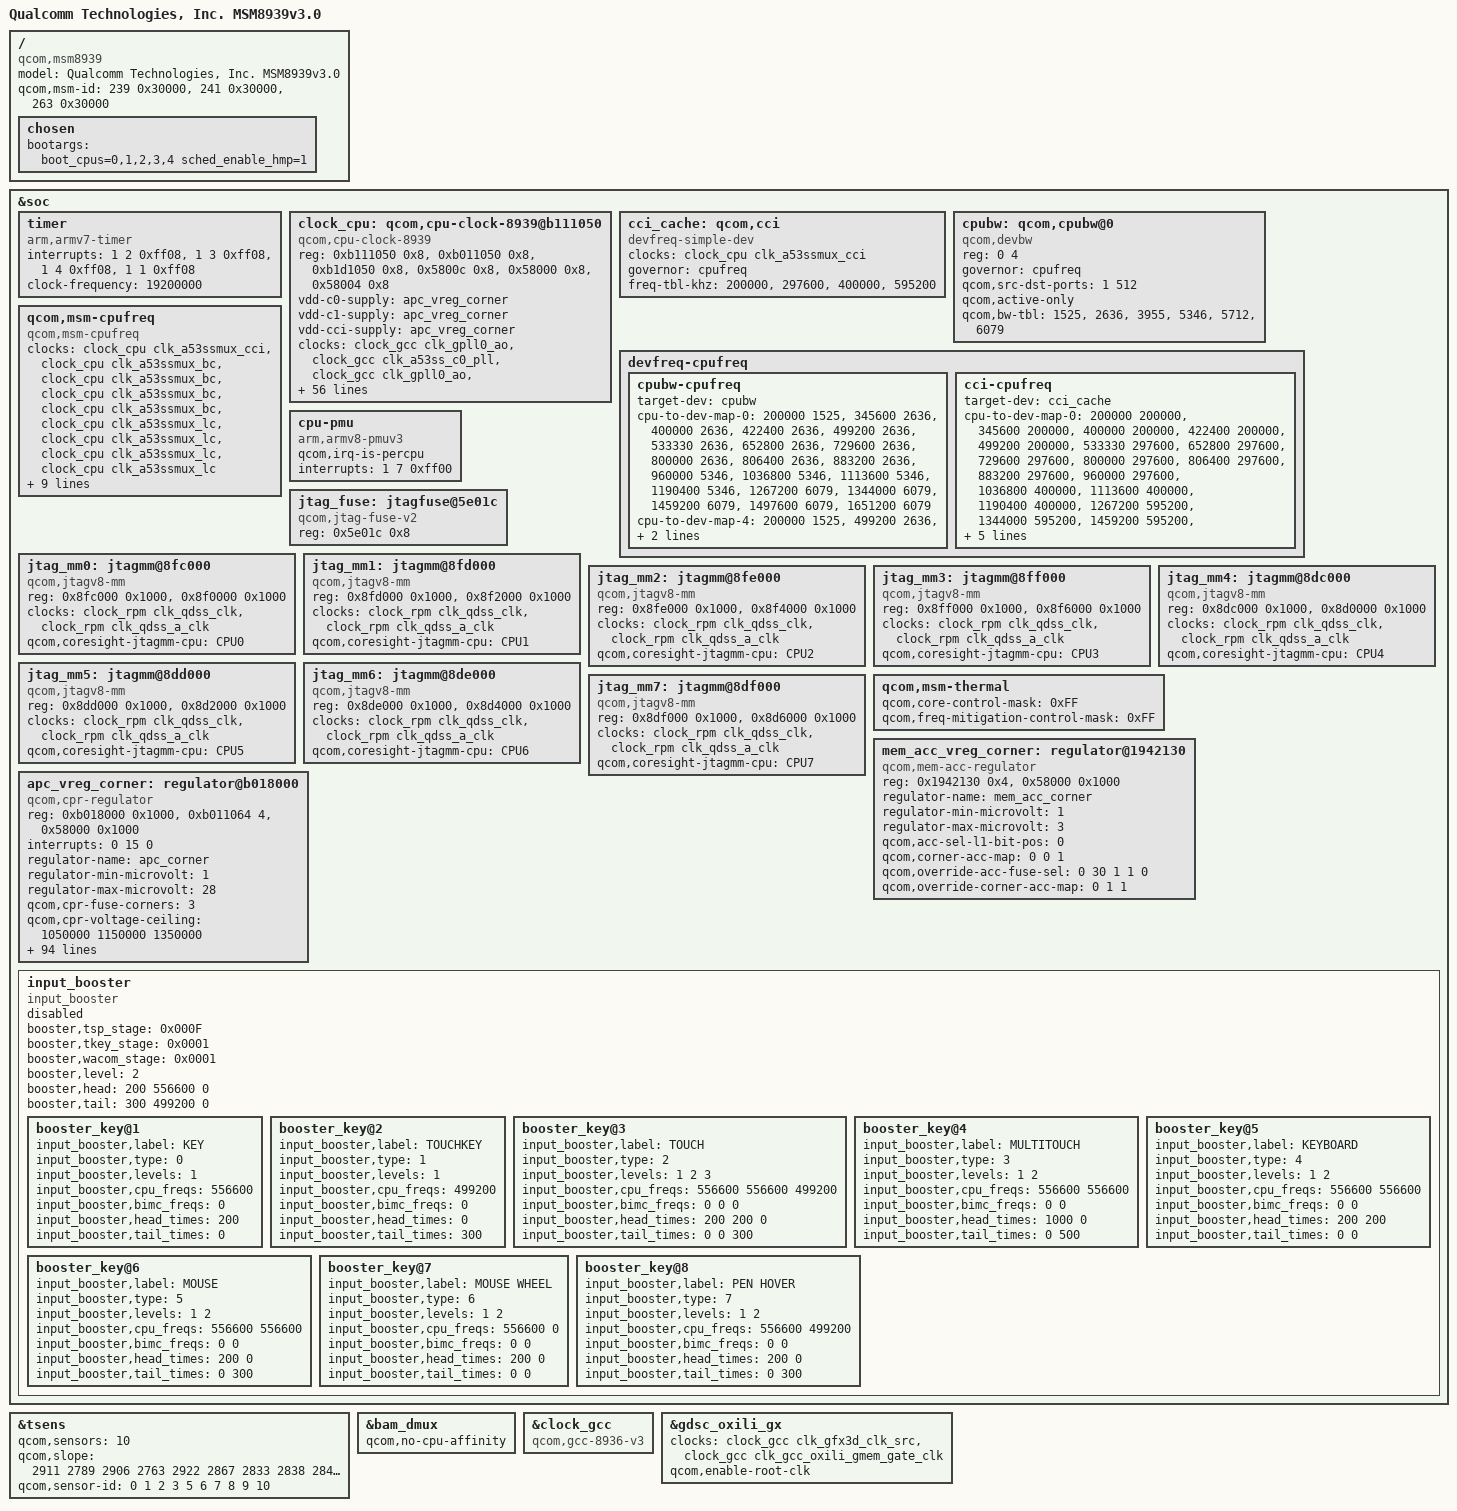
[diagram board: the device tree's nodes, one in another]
/*
 * Copyright (c) 2015, The Linux Foundation. All rights reserved.
 *
 * This program is free software; you can redistribute it and/or modify
 * it under the terms of the GNU General Public License version 2 and
 * only version 2 as published by the Free Software Foundation.
 *
 * This program is distributed in the hope that it will be useful,
 * but WITHOUT ANY WARRANTY; without even the implied warranty of
 * MERCHANTABILITY or FITNESS FOR A PARTICULAR PURPOSE.  See the
 * GNU General Public License for more details.
 */

#include "skeleton64.dtsi"
#include <dt-bindings/clock/msm-clocks-8936.h>
#include <dt-bindings/clock/msm-cpu-clocks-8939.h>
#include "msm8939-common.dtsi"
#include "msm8939-coresight.dtsi"
#include "msm8939-cpu.dtsi"
#include "msm8939-v3.0-pm.dtsi"
#include "msm8939-smem.dtsi"
#include "msm8939-smp2p.dtsi"
#include "msm8939-v3.0-gpu.dtsi"

/ {
	model = "Qualcomm Technologies, Inc. MSM8939v3.0";
	compatible = "qcom,msm8939";
	qcom,msm-id = <239 0x30000>, <241 0x30000>, <263 0x30000>;

	chosen {
		bootargs = "boot_cpus=0,1,2,3,4 sched_enable_hmp=1";
	};
};

&soc {
	timer {
		compatible = "arm,armv7-timer";
		interrupts = <1 2 0xff08>,
			     <1 3 0xff08>,
			     <1 4 0xff08>,
			     <1 1 0xff08>;
		clock-frequency = <19200000>;
	};

	clock_cpu: qcom,cpu-clock-8939@b111050 {
		compatible = "qcom,cpu-clock-8939";
		reg =   <0xb111050 0x8>,
			<0xb011050 0x8>,
			<0xb1d1050 0x8>,
			<0x5800c   0x8>,
			<0x58000   0x8>,
			<0x58004   0x8>;
		reg-names = "apcs-c0-rcg-base", "apcs-c1-rcg-base",
				"apcs-cci-rcg-base", "efuse", "efuse1",
				"efuse2";
		vdd-c0-supply = <&apc_vreg_corner>;
		vdd-c1-supply = <&apc_vreg_corner>;
		vdd-cci-supply = <&apc_vreg_corner>;
		clocks = <&clock_gcc clk_gpll0_ao>,
			 <&clock_gcc clk_a53ss_c0_pll>,
			 <&clock_gcc clk_gpll0_ao>,
			 <&clock_gcc clk_a53ss_c1_pll>,
			 <&clock_gcc clk_gpll0_ao>,
			 <&clock_gcc clk_a53ss_cci_pll>;
		clock-names = "clk-c0-4", "clk-c0-5",
				"clk-c1-4", "clk-c1-5",
				"clk-cci-4", "clk-cci-5";
		qcom,speed0-bin-v0-c0 =
			<          0 0>,
			<  400000000 3>,
			<  500000000 9>,
			<  800000000 12>,
			<  998400000 17>,
			< 1113600000 24>,
			< 1209600000 26>;

		qcom,speed0-bin-v0-c1 =
			<          0 0>,
			<  400000000 3>,
			<  800000000 9>,
			<  960000000 12>,
			< 1113600000 14>,
			< 1344000000 17>;

		qcom,speed0-bin-v0-cci =
			<          0 0>,
			<  200000000 3>,
			<  300000000 12>,
			<  400000000 15>,
			<  600000000 17>;

		qcom,speed2-bin-v0-c0 =
			<          0 0>,
			<  400000000 3>,
			<  500000000 9>,
			<  800000000 12>,
			<  998400000 17>,
			< 1113600000 24>,
			< 1209600000 26>;

		qcom,speed2-bin-v0-c1 =
			<          0 0>,
			<  400000000 3>,
			<  800000000 9>,
			<  806400000 10>,
			<  883200000 11>,
			<  960000000 12>,
			< 1036800000 13>,
			< 1113600000 14>,
			< 1190400000 15>,
			< 1267200000 16>,
			< 1344000000 17>,
			< 1420800000 18>,
			< 1459200000 20>,
			< 1497600000 21>;

		qcom,speed2-bin-v0-cci =
			<          0 0>,
			<  200000000 3>,
			<  300000000 12>,
			<  400000000 15>,
			<  600000000 17>;

		qcom,speed2-bin-v2-c0 =
			<          0 0>,
			<  400000000 3>,
			<  500000000 9>,
			<  800000000 12>,
			<  998400000 17>,
			< 1113600000 24>,
			< 1209600000 26>;

		qcom,speed2-bin-v2-c1 =
			<          0 0>,
			<  400000000 3>,
			<  800000000 9>,
			<  960000000 12>,
			< 1113600000 14>,
			< 1344000000 17>,
			< 1459200000 20>;

		qcom,speed2-bin-v2-cci =
			<          0 0>,
			<  200000000 3>,
			<  300000000 12>,
			<  400000000 15>,
			<  600000000 17>;

		qcom,speed4-bin-v0-c0 =
			<          0 0>,
			<  400000000 3>,
			<  500000000 9>,
			<  800000000 12>,
			<  998400000 17>,
			< 1113600000 24>,
			< 1209600000 26>;

		qcom,speed4-bin-v0-c1 =
			<          0 0>,
			<  400000000 3>,
			<  800000000 9>,
			<  960000000 12>,
			< 1113600000 14>,
			< 1344000000 17>,
			< 1459200000 20>,
			< 1497600000 21>,
			< 1651200000 26>;

		qcom,speed4-bin-v0-cci =
			<          0 0>,
			<  200000000 3>,
			<  300000000 12>,
			<  400000000 15>,
			<  600000000 17>;

		qcom,speed5-bin-v0-c0 =
			<          0 0>,
			<  400000000 3>,
			<  500000000 9>,
			<  800000000 12>,
			<  998400000 17>,
			< 1113600000 24>,
			< 1209600000 26>;

		qcom,speed5-bin-v0-c1 =
			<          0 0>,
			<  400000000 3>,
			<  800000000 9>,
			<  960000000 12>,
			< 1113600000 14>,
			< 1344000000 17>,
			< 1459200000 20>,
			< 1497600000 21>,
			< 1651200000 26>;

		qcom,speed5-bin-v0-cci =
			<          0 0>,
			<  200000000 3>,
			<  300000000 12>,
			<  400000000 15>,
			<  600000000 17>;

		qcom,speed5-bin-v6-c0 =
			<          0 0>,
			<  400000000 3>,
			<  500000000 9>,
			<  800000000 12>,
			<  998400000 17>,
			< 1113600000 24>,
			< 1209600000 26>;

		qcom,speed5-bin-v6-c1 =
			<          0 0>,
			<  400000000 3>,
			<  800000000 9>,
			<  960000000 12>,
			< 1113600000 14>,
			< 1344000000 17>,
			< 1459200000 20>,
			< 1497600000 21>,
			< 1651200000 26>;

		qcom,speed5-bin-v6-cci =
			<          0 0>,
			<  200000000 3>,
			<  300000000 12>,
			<  400000000 15>,
			<  600000000 17>;

		#clock-cells = <1>;
	};

	cci_cache: qcom,cci {
		compatible = "devfreq-simple-dev";
		clock-names = "devfreq_clk";
		clocks = <&clock_cpu clk_a53ssmux_cci>;
		governor = "cpufreq";
		freq-tbl-khz =
			<  200000 >,
			<  297600 >,
			<  400000 >,
			<  595200 >;
	};

	cpubw: qcom,cpubw@0 {
		reg = <0 4>;
		compatible = "qcom,devbw";
		governor = "cpufreq";
		qcom,src-dst-ports = <1 512>;
		qcom,active-only;
		qcom,bw-tbl =
			<  1525 /*  100   MHz */ >,
			<  2636 /*  172.8 MHz */ >,
			<  3955 /*  259.2 MHz */ >,
			<  5346 /*  350.4 MHz */ >,
			<  5712 /*  374.4 MHz */ >,
			<  6079 /*  398.4 MHz */ >;
	};

	devfreq-cpufreq {
		cpubw-cpufreq {
		target-dev = <&cpubw>;
		cpu-to-dev-map-0 =
			<  200000  1525 >,
			<  345600  2636 >,
			<  400000  2636 >,
			<  422400  2636 >,
			<  499200  2636 >,
			<  533330  2636 >,
			<  652800  2636 >,
			<  729600  2636 >,
			<  800000  2636 >,
			<  806400  2636 >,
			<  883200  2636 >,
			<  960000  5346 >,
			<  1036800 5346 >,
			<  1113600 5346 >,
			<  1190400 5346 >,
			<  1267200 6079 >,
			<  1344000 6079 >,
			<  1459200 6079 >,
			<  1497600 6079 >,
			<  1651200 6079 >;
		cpu-to-dev-map-4 =
			<  200000 1525 >,
			<  499200 2636 >,
			<  533330 2636 >,
			<  800000 5346 >,
			<  998400 6079 >,
			< 1113600 6079 >,
			< 1209600 6079 >;
		};

		cci-cpufreq {
		target-dev = <&cci_cache>;
		cpu-to-dev-map-0 =
			<  200000  200000 >,
			<  345600  200000 >,
			<  400000  200000 >,
			<  422400  200000 >,
			<  499200  200000 >,
			<  533330  297600 >,
			<  652800  297600 >,
			<  729600  297600 >,
			<  800000  297600 >,
			<  806400  297600 >,
			<  883200  297600 >,
			<  960000  297600 >,
			< 1036800  400000 >,
			< 1113600  400000 >,
			< 1190400  400000 >,
			< 1267200  595200 >,
			< 1344000  595200 >,
			< 1459200  595200 >,
			< 1497600  595200 >,
			< 1651200  595200 >;
		cpu-to-dev-map-4 =
			<  200000 200000 >,
			<  499200 297600 >,
			<  533330 297600 >,
			<  800000 297600 >,
			<  998400 595200 >,
			< 1113600 595200 >,
			< 1209600 595200 >;
		};
	};

	qcom,msm-cpufreq {
		compatible = "qcom,msm-cpufreq";
		clock-names = "l2_clk", "cpu0_clk", "cpu1_clk", "cpu2_clk",
				"cpu3_clk", "cpu4_clk", "cpu5_clk",
				"cpu6_clk", "cpu7_clk";
		clocks = <&clock_cpu clk_a53ssmux_cci>,
			 <&clock_cpu clk_a53ssmux_bc>,
			 <&clock_cpu clk_a53ssmux_bc>,
			 <&clock_cpu clk_a53ssmux_bc>,
			 <&clock_cpu clk_a53ssmux_bc>,
			 <&clock_cpu clk_a53ssmux_lc>,
			 <&clock_cpu clk_a53ssmux_lc>,
			 <&clock_cpu clk_a53ssmux_lc>,
			 <&clock_cpu clk_a53ssmux_lc>;

		qcom,governor-per-policy;

		qcom,cpufreq-table-0 =
			 <  200000 >,
			 <  345600 >,
			 <  400000 >,
			 <  422400 >,
			 <  499200 >,
			 <  533330 >,
			 <  652800 >,
			 <  729600 >,
			 <  800000 >,
			 <  806400 >,
			 <  883200 >,
			 <  960000 >,
			 < 1036800 >,
			 < 1113600 >,
			 < 1190400 >,
			 < 1267200 >,
			 < 1344000 >,
			 < 1459200 >,
			 < 1497600 >,
			 < 1651200 >;

		qcom,cpufreq-table-4 =
			 <  200000 >,
			 <  249600 >,
			 <  400000 >,
			 <  499200 >,
			 <  533330 >,
			 <  800000 >,
			 <  998400 >,
			 < 1113600 >,
			 < 1209600 >;
	};

	cpu-pmu {
		compatible = "arm,armv8-pmuv3";
		qcom,irq-is-percpu;
		interrupts = <1 7 0xff00>;
	};

	jtag_fuse: jtagfuse@5e01c {
		compatible = "qcom,jtag-fuse-v2";
		reg = <0x5e01c 0x8>;
		reg-names = "fuse-base";
	};

	jtag_mm0: jtagmm@8fc000 {
		compatible = "qcom,jtagv8-mm";
		reg = <0x8fc000 0x1000>,
		      <0x8f0000 0x1000>;
		reg-names = "etm-base", "debug-base";

		clocks = <&clock_rpm clk_qdss_clk>,
		         <&clock_rpm clk_qdss_a_clk>;
		clock-names = "core_clk", "core_a_clk";

		qcom,coresight-jtagmm-cpu = <&CPU0>;
	};

	jtag_mm1: jtagmm@8fd000 {
		compatible = "qcom,jtagv8-mm";
		reg = <0x8fd000 0x1000>,
		      <0x8f2000 0x1000>;
		reg-names = "etm-base", "debug-base";

		clocks = <&clock_rpm clk_qdss_clk>,
		         <&clock_rpm clk_qdss_a_clk>;
		clock-names = "core_clk", "core_a_clk";

		qcom,coresight-jtagmm-cpu = <&CPU1>;
	};

	jtag_mm2: jtagmm@8fe000 {
		compatible = "qcom,jtagv8-mm";
		reg = <0x8fe000 0x1000>,
		      <0x8f4000 0x1000>;
		reg-names = "etm-base", "debug-base";

		clocks = <&clock_rpm clk_qdss_clk>,
		         <&clock_rpm clk_qdss_a_clk>;
		clock-names = "core_clk", "core_a_clk";

		qcom,coresight-jtagmm-cpu = <&CPU2>;
	};

	jtag_mm3: jtagmm@8ff000 {
		compatible = "qcom,jtagv8-mm";
		reg = <0x8ff000 0x1000>,
		      <0x8f6000 0x1000>;
		reg-names = "etm-base", "debug-base";

		clocks = <&clock_rpm clk_qdss_clk>,
		         <&clock_rpm clk_qdss_a_clk>;
		clock-names = "core_clk", "core_a_clk";

		qcom,coresight-jtagmm-cpu = <&CPU3>;
	};

	jtag_mm4: jtagmm@8dc000 {
		compatible = "qcom,jtagv8-mm";
		reg = <0x8dc000 0x1000>,
		      <0x8d0000 0x1000>;
		reg-names = "etm-base", "debug-base";

		clocks = <&clock_rpm clk_qdss_clk>,
		         <&clock_rpm clk_qdss_a_clk>;
		clock-names = "core_clk", "core_a_clk";

		qcom,coresight-jtagmm-cpu = <&CPU4>;
	};

	jtag_mm5: jtagmm@8dd000 {
		compatible = "qcom,jtagv8-mm";
		reg = <0x8dd000 0x1000>,
		      <0x8d2000 0x1000>;
		reg-names = "etm-base", "debug-base";

		clocks = <&clock_rpm clk_qdss_clk>,
		         <&clock_rpm clk_qdss_a_clk>;
		clock-names = "core_clk", "core_a_clk";

		qcom,coresight-jtagmm-cpu = <&CPU5>;
	};

	jtag_mm6: jtagmm@8de000 {
		compatible = "qcom,jtagv8-mm";
		reg = <0x8de000 0x1000>,
		      <0x8d4000 0x1000>;
		reg-names = "etm-base", "debug-base";

		clocks = <&clock_rpm clk_qdss_clk>,
		         <&clock_rpm clk_qdss_a_clk>;
		clock-names = "core_clk", "core_a_clk";

		qcom,coresight-jtagmm-cpu = <&CPU6>;
	};

	jtag_mm7: jtagmm@8df000 {
		compatible = "qcom,jtagv8-mm";
		reg = <0x8df000 0x1000>,
		      <0x8d6000 0x1000>;
		reg-names = "etm-base", "debug-base";

		clocks = <&clock_rpm clk_qdss_clk>,
		         <&clock_rpm clk_qdss_a_clk>;
		clock-names = "core_clk", "core_a_clk";

		qcom,coresight-jtagmm-cpu = <&CPU7>;
	};

	qcom,msm-thermal {
		qcom,core-control-mask = <0xFF>;
		qcom,freq-mitigation-control-mask = <0xFF>;
	};

	/delete-node/ regulator@b018000;

      /delete-node/ regulator@1942130;

      mem_acc_vreg_corner: regulator@1942130 {
             compatible = "qcom,mem-acc-regulator";
             reg = <0x1942130 0x4>, <0x58000 0x1000>;
             reg-names = "acc-sel-l1", "efuse_addr";
             regulator-name = "mem_acc_corner";
             regulator-min-microvolt = <1>;
             regulator-max-microvolt = <3>;

             qcom,acc-sel-l1-bit-pos = <0>;
             qcom,corner-acc-map = <0 0 1>;

             qcom,override-acc-fuse-sel = <0 30 1 1 0>;
             qcom,override-corner-acc-map = <0 1 1>;
       };

	apc_vreg_corner: regulator@b018000 {
		compatible = "qcom,cpr-regulator";
		reg = <0xb018000 0x1000>, <0xb011064 4>, <0x58000 0x1000>;
		reg-names = "rbcpr", "rbcpr_clk", "efuse_addr";
		interrupts = <0 15 0>;
		regulator-name = "apc_corner";
		regulator-min-microvolt = <1>;
		regulator-max-microvolt = <28>;

		qcom,cpr-fuse-corners = <3>;
		qcom,cpr-voltage-ceiling = <1050000 1150000 1350000>;
		qcom,cpr-voltage-floor = <1050000 1050000 1137500>;
		vdd-apc-supply = <&ncp6335d>;

		qcom,vdd-mx-corner-map = <4 5 7>;
		qcom,vdd-mx-vmin-method = <4>;
		vdd-mx-supply = <&pm8916_l3_corner_ao>;
		qcom,vdd-mx-vmax = <7>;

		mem-acc-supply = <&mem_acc_vreg_corner>;

		qcom,cpr-ref-clk = <19200>;
		qcom,cpr-timer-delay = <5000>;
		qcom,cpr-timer-cons-up = <0>;
		qcom,cpr-timer-cons-down = <2>;
		qcom,cpr-irq-line = <0>;
		qcom,cpr-step-quotient = <13>;
		qcom,cpr-up-threshold = <0>;
		qcom,cpr-down-threshold = <8>;
		qcom,cpr-idle-clocks = <15>;
		qcom,cpr-gcnt-time = <1>;
		qcom,vdd-apc-step-up-limit = <1>;
		qcom,vdd-apc-step-down-limit = <1>;
		qcom,cpr-apc-volt-step = <6250>;

		qcom,cpr-fuse-row = <27 0>;
		qcom,cpr-fuse-target-quot = <42 24 6>;
		qcom,cpr-fuse-ro-sel = <54 54 54>;
		qcom,cpr-quot-min-diff = <0>;
		qcom,cpr-init-voltage-ref = <1050000 1150000 1350000>;
		qcom,cpr-fuse-init-voltage =
					<27 36 6 0>,
					<27 18 6 0>,
					<27 0 6 0>;
		qcom,cpr-init-voltage-step = <10000>;
		qcom,cpr-scaled-init-voltage-as-ceiling;
		qcom,cpr-corner-map = <1 1 1 2 2 2 2 2 2 2 2 2 2 2 3 3 3 3 3 3
					3 3 3 3 3 3 3 3>;
		qcom,cpr-corner-frequency-map =
					<1 200000000>,
					<2 345600000>,
					<3 400000000>,
					<4 422400000>,
					<5 499200000>,
					<6 533330000>,
					<7 652800000>,
					<8 729600000>,
					<9 800000000>,
					<10 806400000>,
					<11 883200000>,
					<12 960000000>,
					<13 1036800000>,
					<14 1113600000>,
					<15 1190400000>,
					<16 1267200000>,
					<17 1344000000>,
					<18 1363200000>,
					<19 1420800000>,
					<20 1459200000>,
					<21 1497600000>,
					<22 1536000000>,
					<23 1574400000>,
					<24 1612800000>,
					<25 1632000000>,
					<26 1651200000>,
					<27 1689600000>,
					<28 1708800000>;
		qcom,speed-bin-fuse-sel = <1 34 3 0>;
		qcom,fuse-remap-base-row = <1000>;
		qcom,fuse-remap-source =
					<0 29 1 0>, /* speed bit[0]	*/
					<0 50 2 0>, /* speed bit[2:1]  */
					<0 30 1 0>; /* ACC Override Bit       */
		qcom,pvs-version-fuse-sel = <1000 0 3 0>;
		qcom,cpr-fuse-revision = <1000 3 1 0>;
		qcom,cpr-speed-bin-max-corners =
					<0 0 3 14 17>,
					<2 0 3 14 21>,
					<2 2 3 14 20>,
					<5 0 3 14 26>,
					<5 6 3 14 26>;
		qcom,cpr-quot-adjust-scaling-factor-max = <1400>;
		qcom,cpr-fuse-version-map =
		/* <Speed_bits   PVS_version   CPR_Rev - - -> */
                      <2          2          0 0xffffffff 0xffffffff 0xffffffff>,
                      <2          2          1 0xffffffff 0xffffffff 0xffffffff>,
                      <2          0          0 0xffffffff 0xffffffff 0xffffffff>,
                      <2          0          1 0xffffffff 0xffffffff 0xffffffff>,
                      <5          0xffffffff 0 0xffffffff 0xffffffff 0xffffffff>,
                      <5          0xffffffff 1 0xffffffff 0xffffffff 0xffffffff>,
                      <0xffffffff 0xffffffff 0 0xffffffff 0xffffffff 0xffffffff>,
                      <0xffffffff 0xffffffff 1 0xffffffff 0xffffffff 0xffffffff>;
		qcom,cpr-init-voltage-adjustment =
                                     <0   20000  0>,
                                     <0   45000  0>,
                                     <0   20000  0>,
                                     <0   45000  0>,
                                     <0   20000  0>,
                                     <0   45000  0>,
                                     <0   20000  0>,
                                     <0   45000  0>;
		qcom,cpr-quotient-adjustment =
                                     <0   41   (-124)>, /*NOM + 20mv, TURBO - 60mv */
                                     <0   93   (-124)>, /*NOM + 45mv, TURBO - 60mv */
                                     <0   41   (-41)>, /* NOM + 20mv, TURBO - 20mv */
                                     <0   93   (-41)>, /* NOM + 45mv, TURBO - 20mv */
                                     <0   41   (-41)>, /* NOM + 20mv, TURBO - 20mv */
                                     <0   93   (-41)>, /* NOM + 45mv, TURBO - 20mv */
                                     <0   41   (-41)>, /* NOM + 20mv, TURBO - 20mv */
                                     <0   93   (-41)>; /* NOM + 45mv, TURBO - 20mv */
		qcom,cpr-fuse-min-quot-diff = <0 0 40>;
		qcom,cpr-min-quot-diff-adjustment =
                                     <0 0 40>,
                                     <0 0 40>,
                                     <0 0 40>,
                                     <0 0 40>,
                                     <0 0 40>,
                                     <0 0 40>,
                                     <0 0 40>,
                                     <0 0 40>;
		qcom,cpr-virtual-corner-quotient-adjustment =
                       <0 0 0 (-104) (-104) (-104) (-104) (-104) (-104) (-104)
                        (-104) (-41) (-41) (41) 0 0 (-52) 0 0 0 0 (124) 0 0 0 0 0 0>,
                       <0 0 0 (-104) (-104) (-104) (-104) (-104) (-104) (-104)
                       (-104) (-41) (-41) (41) 0 0 (-52) 0 0 0 0 (124) 0 0 0 0 0 0>,
                       <0 0 0 (-104) (-104) (-104) (-104) (-104) (-104) (-104)
                        (-104) (-41) (-41) (41) 0 0 (-52) 0 0 0 0 (42) 0 0 0 0 0 0>,
                       <0 0 0 (-104) (-104) (-104) (-104) (-104) (-104) (-104)
                       (-104) (-41) (-41) (41) 0 0 (-52) 0 0 0 0 (42) 0 0 0 0 0 0>,
                       <0 0 0 (-104) (-104) (-104) (-104) (-104) (-104) (-104)
                       (-104) (-41) (-41) (41) 0 0 (-52) 0 0 0  (-52) 0 0 0 0 0 0 0>,
                       <0 0 0 (-104) (-104) (-104) (-104) (-104) (-104) (-104)
                        (-104) (-41) (-41) (41) 0 0 (-52) 0 0 0  (-52) 0 0 0 0 0 0 0>,
                       <0 0 0 (-104) (-104) (-104) (-104) (-104) (-104) (-104)
                       (-104) (-41) (-41) 0 0 0 0 0 0 0   0 0 0 0 0 0 0 0>,
                       <0 0 0 (-104) (-104) (-104) (-104) (-104) (-104) (-104)
                        (-104) (-41) (-41) 0 0 0 0 0 0 0   0 0 0 0 0 0 0 0>;
		qcom,cpr-virtual-corner-init-voltage-adjustment =
                       <0 0 0 0 0 0 0 0 0 0 0 0 0 (20000) 0 0 0 0 0 0 0 (20000) 0 0 0 0 0 0>,
                       <0 0 0 0 0 0 0 0 0 0 0 0 0 (20000) 0 0 0 0 0 0 0 (20000) 0 0 0 0 0 0>,
                       <0 0 0 0 0 0 0 0 0 0 0 0 0 (20000) 0 0 0 0 0 0 0 (20000) 0 0 0 0 0 0>,
                       <0 0 0 0 0 0 0 0 0 0 0 0 0 (20000) 0 0 0 0 0 0 0 (20000) 0 0 0 0 0 0>,
                       <0 0 0 0 0 0 0 0 0 0 0 0 0 (20000) 0 0 0 0 0 0 0 0 0 0 0 0 0 0>,
                       <0 0 0 0 0 0 0 0 0 0 0 0 0 (20000) 0 0 0 0 0 0 0 0 0 0 0 0 0 0>,
                       <0 0 0 0 0 0 0 0 0 0 0 0 0 0 0 0 0 0 0 0 0 0 0 0 0 0 0 0>,
                       <0 0 0 0 0 0 0 0 0 0 0 0 0 0 0 0 0 0 0 0 0 0 0 0 0 0 0 0>;
		qcom,cpr-voltage-floor-override =
			<0xffffffff 0xffffffff 1050000 1050000 1050000 1050000
			1050000 1050000 1050000 1050000 1050000 1050000 1050000
			1050000 1050000 1100000 1137500 1137500 1137500 1137500
			1137500 1137500 1137500 1137500 1137500 1137500 1137500
			1137500 1137500 1137500>;
		qcom,cpr-enable;
	};
};

&soc {
	/* Samsung Feature for all MSM8939 models */
	input_booster {
		status = "disabled";
		compatible = "input_booster";
		#address-cells = <1>;
		#size-cells = <0>;

	/*	DVFS_STAGE_NONE		0x0001	: 0000 0000 0000 0001
		DVFS_STAGE_SINGLE	0x0002	: 0000 0000 0000 0010
		DVFS_STAGE_DUAL		0x0004	: 0000 0000 0000 0100
		DVFS_STAGE_TRIPLE	0x0008	: 0000 0000 0000 1000 */

		booster,tsp_stage = <0x000F>;	// supported stage with OR operation
		booster,tkey_stage = <0x0001>;	// supported stage with OR operation
		booster,wacom_stage = <0x0001>;	// supported stage with OR operation

		booster,level = <2>;			// default level
		booster,head = <200 556600 0>;	// default head value <time cpu_freq bimc_freq>
		booster,tail = <300 499200 0>;	// default tail value <time cpu_freq bimc_freq>

		booster_key@1 {
			input_booster,label = "KEY";
			input_booster,type = <0>;	/* BOOSTER_DEVICE_KEY */

			input_booster,levels = <1>;

			/* Frequency table */
			/* for level	:	1_Head */
			input_booster,cpu_freqs = <556600>;
			input_booster,bimc_freqs = <0>;

			/* Time table */
			input_booster,head_times = <200>;
			input_booster,tail_times = <0>;

		};
		booster_key@2 {
			input_booster,label = "TOUCHKEY";
			input_booster,type = <1>;	/* BOOSTER_DEVICE_TOUCHKEY */

			input_booster,levels = <1>;

			/* Frequency table */
			/* for level	:	1_Head */
			input_booster,cpu_freqs = <499200>;
			input_booster,bimc_freqs = <0>;

			/* Time table */
			input_booster,head_times = <0>;
			input_booster,tail_times = <300>;
		};
		booster_key@3 {
			input_booster,label = "TOUCH";
			input_booster,type = <2>;	/* BOOSTER_DEVICE_TOUCH */

			input_booster,levels = <1 2 3>;

			/* Frequency table */
			/* for level	:	1_Head, 2_Head, 2_Tail */
			input_booster,cpu_freqs = <556600 556600 499200>;
			input_booster,bimc_freqs = <0 0 0>;

			/* Time table */
			input_booster,head_times = <200 200 0>;
			input_booster,tail_times = <0 0 300>;
		};
		booster_key@4 { // Input Booster +
			input_booster,label = "MULTITOUCH";
			input_booster,type = <3>;	/* BOOSTER_DEVICE_MULTITOUCH */

			input_booster,levels = <1 2>;

			/* Frequency table */
			/* for level	:	1_Head 2_Tail*/
			input_booster,cpu_freqs = <556600 556600>;
			input_booster,bimc_freqs = <0 0>;

			/* Time table */
			input_booster,head_times = <1000 0>;
			input_booster,tail_times = <0 500>;
		};
		booster_key@5 {
			input_booster,label = "KEYBOARD";
			input_booster,type = <4>;	/* BOOSTER_DEVICE_KEYBOARD */

			input_booster,levels = <1 2>;

			/* Frequency table */
			/* for level	:	1_Head 2_Tail*/
			input_booster,cpu_freqs = <556600 556600>;
			input_booster,bimc_freqs = <0 0>;

			/* Time table */
			input_booster,head_times = <200 200>;
			input_booster,tail_times = <0 0>;
		};
		booster_key@6 {
			input_booster,label = "MOUSE";
			input_booster,type = <5>;	/* BOOSTER_DEVICE_MOUSE */

			input_booster,levels = <1 2>;

			/* Frequency table */
			/* for level	:	1_Head 2_Tail*/
			input_booster,cpu_freqs = <556600 556600>;
			input_booster,bimc_freqs = <0 0>;

			/* Time table */
			input_booster,head_times = <200 0>;
			input_booster,tail_times = <0 300>;
		};
		booster_key@7 {
			input_booster,label = "MOUSE WHEEL";
			input_booster,type = <6>;	/* BOOSTER_DEVICE_MOUSE */

			input_booster,levels = <1 2>;

			/* Frequency table */
			/* for level	:	1_Head 2_Tail*/
			input_booster,cpu_freqs = <556600 0>;
			input_booster,bimc_freqs = <0 0>;

			/* Time table */
			input_booster,head_times = <200 0>;
			input_booster,tail_times = <0 0>;
		};
		booster_key@8 {
			input_booster,label = "PEN HOVER";
			input_booster,type = <7>;	/* BOOSTER_DEVICE_MOUSE */

			input_booster,levels = <1 2>;

			/* Frequency table */
			/* for level	:	1_Head 2_Tail*/
			input_booster,cpu_freqs = <556600 499200>;
			input_booster,bimc_freqs = <0 0>;

			/* Time table */
			input_booster,head_times = <200 0>;
			input_booster,tail_times = <0 300>;
		}; // Input Booster -
	};
};


&tsens {
	qcom,sensors = <10>;
	qcom,slope = <2911 2789 2906 2763 2922 2867 2833 2838 2840 2852>;
	qcom,sensor-id = <0 1 2 3 5 6 7 8 9 10>;
};

&bam_dmux {
	qcom,no-cpu-affinity;
};

&clock_gcc {
	compatible = "qcom,gcc-8936-v3";
};

&gdsc_oxili_gx {
	clock-names = "core_root_clk", "gmem_clk";
	clocks = <&clock_gcc clk_gfx3d_clk_src>,
	         <&clock_gcc  clk_gcc_oxili_gmem_gate_clk>;
	qcom,enable-root-clk;
	status = "okay";
};
